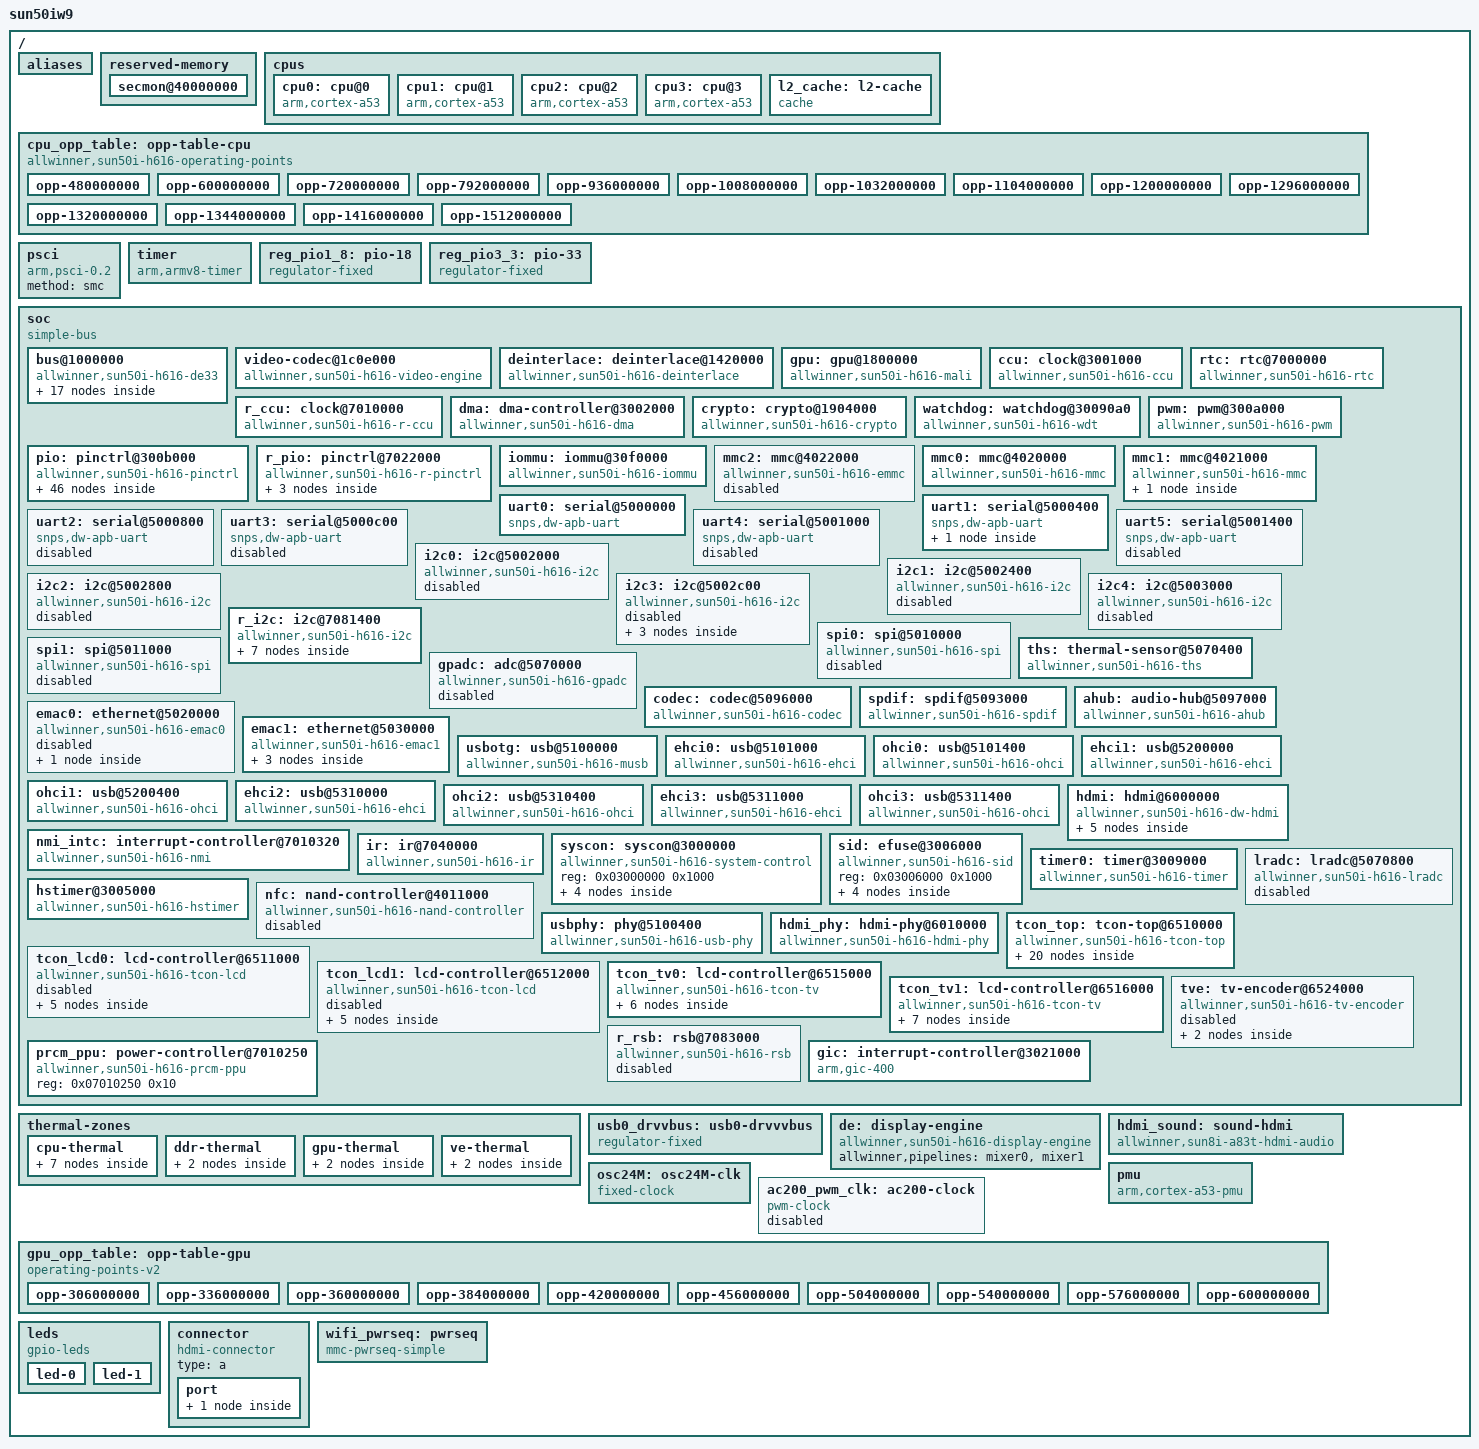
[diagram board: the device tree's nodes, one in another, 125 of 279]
/dts-v1/;

/* dt-bindings from torvalds/linux v6.18 (7d0a66e4bb9081d75c82ec4957c50034cb0ea449), include/ */
#include <dt-bindings/clock/sun50i-h616-ccu.h>
#include <dt-bindings/clock/sun50i-h6-r-ccu.h>
#include <dt-bindings/clock/sun6i-rtc.h>
#include <dt-bindings/clock/sun8i-de2.h>
#include <dt-bindings/clock/sun8i-tcon-top.h>
#include <dt-bindings/reset/sun50i-h616-ccu.h>
#include <dt-bindings/reset/sun50i-h6-r-ccu.h>
#include <dt-bindings/reset/sun8i-de2.h>
#include <dt-bindings/gpio/gpio.h>
#include <dt-bindings/interrupt-controller/arm-gic.h>
#include <dt-bindings/interrupt-controller/irq.h>
#include <dt-bindings/input/linux-event-codes.h>
#include <dt-bindings/leds/common.h>
#include <dt-bindings/thermal/thermal.h>

/ {
	interrupt-parent = <&gic>;
	#address-cells = <2>;
	#size-cells = <2>;
	model = "sun50iw9";

	aliases {
		serial0 = &uart0;
		serial1 = &uart1;
		serial2 = &uart2;
		serial3 = &uart3;
		serial4 = &uart4;
		serial5 = &uart5;
		mmc0 = &mmc0;
		mmc2 = &mmc2;
		spi0 = &spi0;
		spi1 = &spi1;
	};

	reserved-memory {
		#address-cells = <2>;
		#size-cells = <2>;
		ranges;

		/*
		 * 256 KiB reserved for Trusted Firmware-A (BL31).
		 * This is added by BL31 itself, but some bootloaders fail
		 * to propagate this into the DTB handed to kernels.
		 */
		secmon@40000000 {
			reg = <0x0 0x40000000 0x0 0x40000>;
			no-map;
		};
	};

	cpus {
		#address-cells = <1>;
		#size-cells = <0>;

		cpu0: cpu@0 {
			compatible = "arm,cortex-a53";
			device_type = "cpu";
			reg = <0>;
			enable-method = "psci";
			clocks = <&ccu CLK_CPUX>;
			#cooling-cells = <2>;
			i-cache-size = <0x8000>;
			i-cache-line-size = <64>;
			i-cache-sets = <256>;
			d-cache-size = <0x8000>;
			d-cache-line-size = <64>;
			d-cache-sets = <128>;
			next-level-cache = <&l2_cache>;
			operating-points-v2 = <&cpu_opp_table>;
			dynamic-power-coefficient = <202>;
			cpu-supply = <&reg_dcdc2>;
		};

		cpu1: cpu@1 {
			compatible = "arm,cortex-a53";
			device_type = "cpu";
			reg = <1>;
			enable-method = "psci";
			clocks = <&ccu CLK_CPUX>;
			#cooling-cells = <2>;
			i-cache-size = <0x8000>;
			i-cache-line-size = <64>;
			i-cache-sets = <256>;
			d-cache-size = <0x8000>;
			d-cache-line-size = <64>;
			d-cache-sets = <128>;
			next-level-cache = <&l2_cache>;
			operating-points-v2 = <&cpu_opp_table>;
			dynamic-power-coefficient = <202>;
		};

		cpu2: cpu@2 {
			compatible = "arm,cortex-a53";
			device_type = "cpu";
			reg = <2>;
			enable-method = "psci";
			clocks = <&ccu CLK_CPUX>;
			#cooling-cells = <2>;
			i-cache-size = <0x8000>;
			i-cache-line-size = <64>;
			i-cache-sets = <256>;
			d-cache-size = <0x8000>;
			d-cache-line-size = <64>;
			d-cache-sets = <128>;
			next-level-cache = <&l2_cache>;
			operating-points-v2 = <&cpu_opp_table>;
			dynamic-power-coefficient = <202>;
		};

		cpu3: cpu@3 {
			compatible = "arm,cortex-a53";
			device_type = "cpu";
			reg = <3>;
			enable-method = "psci";
			clocks = <&ccu CLK_CPUX>;
			#cooling-cells = <2>;
			i-cache-size = <0x8000>;
			i-cache-line-size = <64>;
			i-cache-sets = <256>;
			d-cache-size = <0x8000>;
			d-cache-line-size = <64>;
			d-cache-sets = <128>;
			next-level-cache = <&l2_cache>;
			operating-points-v2 = <&cpu_opp_table>;
			dynamic-power-coefficient = <202>;
		};

		l2_cache: l2-cache {
			compatible = "cache";
			cache-level = <2>;
			cache-unified;
			cache-size = <0x40000>;
			cache-line-size = <64>;
			cache-sets = <256>;
		};
	};

	cpu_opp_table: opp-table-cpu {
		compatible = "allwinner,sun50i-h616-operating-points";
		nvmem-cells = <&cpu_speed_grade>;
		opp-shared;

		opp-480000000 {
			opp-hz = /bits/ 64 <480000000>;
			opp-microvolt-speed0 = <900000>;
			opp-microvolt-speed1 = <900000>;
			opp-microvolt-speed2 = <900000>;
			opp-microvolt-speed3 = <900000>;
			opp-microvolt-speed4 = <900000>;
			clock-latency-ns = <244144>;
			opp-supported-hw = <0x1f>;
		};

		opp-600000000 {
			opp-hz = /bits/ 64 <600000000>;
			opp-microvolt-speed1 = <900000>;
			opp-microvolt-speed4 = <900000>;
			clock-latency-ns = <244144>;
			opp-supported-hw = <0x12>;
		};

		opp-720000000 {
			opp-hz = /bits/ 64 <720000000>;
			opp-microvolt-speed0 = <900000>;
			opp-microvolt-speed2 = <900000>;
			opp-microvolt-speed3 = <900000>;
			clock-latency-ns = <244144>;
			opp-supported-hw = <0x0d>;
		};

		opp-792000000 {
			opp-hz = /bits/ 64 <792000000>;
			opp-microvolt-speed1 = <900000>;
			opp-microvolt-speed4 = <940000>;
			clock-latency-ns = <244144>;
			opp-supported-hw = <0x12>;
		};

		opp-936000000 {
			opp-hz = /bits/ 64 <936000000>;
			opp-microvolt-speed2 = <900000>;
			opp-microvolt-speed3 = <900000>;
			clock-latency-ns = <244144>;
			opp-supported-hw = <0x0c>;
		};

		opp-1008000000 {
			opp-hz = /bits/ 64 <1008000000>;
			opp-microvolt-speed1 = <940000>;
			opp-microvolt-speed2 = <950000>;
			opp-microvolt-speed3 = <950000>;
			opp-microvolt-speed4 = <1020000>;
			clock-latency-ns = <244144>;
			opp-supported-hw = <0x1e>;
		};

		opp-1032000000 {
			opp-hz = /bits/ 64 <1032000000>;
			opp-microvolt-speed0 = <900000>;
			clock-latency-ns = <244144>;
			opp-supported-hw = <0x01>;
		};

		opp-1104000000 {
			opp-hz = /bits/ 64 <1104000000>;
			opp-microvolt-speed0 = <950000>;
			opp-microvolt-speed2 = <1000000>;
			opp-microvolt-speed3 = <1000000>;
			clock-latency-ns = <244144>;
			opp-supported-hw = <0x0d>;
		};

		opp-1200000000 {
			opp-hz = /bits/ 64 <1200000000>;
			opp-microvolt-speed0 = <1000000>;
			opp-microvolt-speed1 = <1020000>;
			opp-microvolt-speed2 = <1050000>;
			opp-microvolt-speed3 = <1050000>;
			opp-microvolt-speed4 = <1100000>;
			clock-latency-ns = <244144>;
			opp-supported-hw = <0x1f>;
		};

		opp-1296000000 {
			opp-hz = /bits/ 64 <1296000000>;
			opp-microvolt-speed0 = <1050000>;
			clock-latency-ns = <244144>;
			opp-supported-hw = <0x01>;
		};

		opp-1320000000 {
			opp-hz = /bits/ 64 <1320000000>;
			opp-microvolt-speed2 = <1100000>;
			opp-microvolt-speed3 = <1100000>;
			clock-latency-ns = <244144>;
			opp-supported-hw = <0x0c>;
		};

		opp-1344000000 {
			opp-hz = /bits/ 64 <1344000000>;
			opp-microvolt-speed4 = <1120000>;
			clock-latency-ns = <244144>;
			opp-supported-hw = <0x10>;
		};

		opp-1416000000 {
			opp-hz = /bits/ 64 <1416000000>;
			opp-microvolt-speed0 = <1100000>;
			opp-microvolt-speed2 = <1150000>;
			opp-microvolt-speed3 = <1160000>;
			clock-latency-ns = <244144>;
			opp-supported-hw = <0x0d>;
		};

		opp-1512000000 {
			opp-hz = /bits/ 64 <1512000000>;
			opp-microvolt-speed0 = <1150000>;
			opp-microvolt-speed1 = <1100000>;
			opp-microvolt-speed3 = <1100000>;
			clock-latency-ns = <244144>;
			opp-supported-hw = <0x0b>;
		};
	};

	psci {
		compatible = "arm,psci-0.2";
		method = "smc";
	};

	timer {
		compatible = "arm,armv8-timer";
		arm,no-tick-in-suspend;
		interrupts = <GIC_PPI 13
			(GIC_CPU_MASK_SIMPLE(4) | IRQ_TYPE_LEVEL_HIGH)>,
			     <GIC_PPI 14
			(GIC_CPU_MASK_SIMPLE(4) | IRQ_TYPE_LEVEL_HIGH)>,
			     <GIC_PPI 11
			(GIC_CPU_MASK_SIMPLE(4) | IRQ_TYPE_LEVEL_HIGH)>,
			     <GIC_PPI 10
			(GIC_CPU_MASK_SIMPLE(4) | IRQ_TYPE_LEVEL_HIGH)>;
	};

	reg_pio1_8: pio-18 {
		compatible = "regulator-fixed";
		regulator-name = "pio-18";
		regulator-min-microvolt = <1800000>;
		regulator-max-microvolt = <1800000>;
	};

	reg_pio3_3: pio-33 {
		compatible = "regulator-fixed";
		regulator-name = "pio-33";
		regulator-min-microvolt = <3300000>;
		regulator-max-microvolt = <3300000>;
	};

	soc {
		compatible = "simple-bus";
		#address-cells = <1>;
		#size-cells = <1>;
		ranges = <0x0 0x0 0x0 0x40000000>;

		bus@1000000 {
			compatible = "allwinner,sun50i-h616-de33",
				     "allwinner,sun50i-a64-de2";
			reg = <0x1000000 0x400000>;
			allwinner,sram = <&sram_c 1>;
			#address-cells = <1>;
			#size-cells = <1>;
			ranges = <0 0x1000000 0x400000>;

			display_clocks: clock@8000 {
				compatible = "allwinner,sun50i-h616-de33-clk";
				reg = <0x8000 0x100>;
				clocks = <&ccu CLK_BUS_DE>, <&ccu CLK_DE>;
				clock-names = "bus", "mod";
				resets = <&ccu RST_BUS_DE>;
				#clock-cells = <1>;
				#reset-cells = <1>;
			};

			writeback: writeback@11000 {
				compatible = "allwinner,sun50i-h616-de33-wb";
				reg = <0x11000 0x1000>, <0x8200 0x20>;
				reg-names = "writeback", "rcq";
				clocks = <&display_clocks CLK_BUS_MIXER0>,
					 <&display_clocks CLK_WB>;
				clock-names = "bus", "mod";
				resets = <&display_clocks RST_WB>;
				interrupts = <GIC_SPI 88 IRQ_TYPE_LEVEL_HIGH>;
				allwinner,top = <&display_clocks>;

				ports {
					#address-cells = <1>;
					#size-cells = <0>;

					writeback_in: port@0 {
						#address-cells = <1>;
						#size-cells = <0>;
						reg = <0>;

						writeback_in_mixer0: endpoint@0 {
							reg = <0>;
							remote-endpoint = <&mixer0_out_writeback>;
						};

						writeback_in_mixer1: endpoint@1 {
							reg = <1>;
							remote-endpoint = <&mixer1_out_writeback>;
						};
					};
				};
			};

			planes: planes@100000 {
				compatible = "allwinner,sun50i-h616-de33-planes";
				reg = <0x100000 0x180000>;
				iommus = <&iommu 0>;
				allwinner,plane-mapping = <&display_clocks>;
			};

			mixer0: mixer@280000 {
				compatible = "allwinner,sun50i-h616-de33-mixer-0";
				reg = <0x280000 0x20000>,
				      <0x8100 0x40>;
				reg-names = "display", "top";
				clocks = <&display_clocks CLK_BUS_MIXER0>,
					 <&display_clocks CLK_MIXER0>;
				clock-names = "bus", "mod";
				resets = <&display_clocks RST_MIXER0>;
				iommus = <&iommu 0>;
				allwinner,planes = <&planes>;

				ports {
					#address-cells = <1>;
					#size-cells = <0>;

					mixer0_out: port@1 {
						#address-cells = <1>;
						#size-cells = <0>;
						reg = <1>;

						mixer0_out_tcon_top_mixer0: endpoint@0 {
							reg = <0>;
							remote-endpoint =
								<&tcon_top_mixer0_in_mixer0>;
						};

						mixer0_out_writeback: endpoint@1 {
							reg = <1>;
							remote-endpoint = <&writeback_in_mixer0>;
						};
					};
				};
			};

			mixer1: mixer@2a0000 {
				compatible = "allwinner,sun50i-h616-de33-mixer-0";
				reg = <0x2a0000 0x20000>,
				      <0x8140 0x40>;
				reg-names = "display", "top";
				clocks = <&display_clocks CLK_BUS_MIXER0>,
					 <&display_clocks CLK_MIXER1>;
				clock-names = "bus", "mod";
				resets = <&display_clocks RST_MIXER1>;
				allwinner,planes = <&planes>;

				ports {
					#address-cells = <1>;
					#size-cells = <0>;

					mixer1_out: port@1 {
						#address-cells = <1>;
						#size-cells = <0>;
						reg = <1>;

						mixer1_out_tcon_top_mixer1: endpoint@0 {
							reg = <0>;
							remote-endpoint =
								<&tcon_top_mixer1_in_mixer1>;
						};

						mixer1_out_writeback: endpoint@1 {
							reg = <1>;
							remote-endpoint = <&writeback_in_mixer1>;
						};
					};
				};
			};
		};

		video-codec@1c0e000 {
			compatible = "allwinner,sun50i-h616-video-engine";
			reg = <0x01c0e000 0x2000>;
			clocks = <&ccu CLK_BUS_VE>, <&ccu CLK_VE>,
				 <&ccu CLK_MBUS_VE>;
			clock-names = "ahb", "mod", "ram";
			resets = <&ccu RST_BUS_VE>;
			interrupts = <GIC_SPI 93 IRQ_TYPE_LEVEL_HIGH>;
			iommus = <&iommu 3>, <&iommu 2>;
			allwinner,sram = <&ve_sram 1>, <&sram_c 1>;
		};

		deinterlace: deinterlace@1420000 {
			compatible = "allwinner,sun50i-h616-deinterlace";
			reg = <0x01420000 0x40000>;
			clocks = <&ccu CLK_BUS_DEINTERLACE>,
				 <&ccu CLK_DEINTERLACE>;
			clock-names = "bus", "mod";
			resets = <&ccu RST_BUS_DEINTERLACE>;
			interrupts = <GIC_SPI 89 IRQ_TYPE_LEVEL_HIGH>;
			iommus = <&iommu 1>;
		};

		gpu: gpu@1800000 {
			compatible = "allwinner,sun50i-h616-mali",
				     "arm,mali-bifrost";
			reg = <0x1800000 0x40000>;
			interrupts = <GIC_SPI 95 IRQ_TYPE_LEVEL_HIGH>,
				     <GIC_SPI 96 IRQ_TYPE_LEVEL_HIGH>,
				     <GIC_SPI 97 IRQ_TYPE_LEVEL_HIGH>;
			interrupt-names = "job", "mmu", "gpu";
			clocks = <&ccu CLK_GPU0>, <&ccu CLK_BUS_GPU>;
			clock-names = "core", "bus";
			power-domains = <&prcm_ppu 2>;
			resets = <&ccu RST_BUS_GPU>;
			#cooling-cells = <2>;
			operating-points-v2 = <&gpu_opp_table>;
			status = "okay";
			mali-supply = <&reg_dcdc1>;
		};

		ccu: clock@3001000 {
			compatible = "allwinner,sun50i-h616-ccu";
			reg = <0x03001000 0x1000>;
			clocks = <&osc24M>, <&rtc CLK_OSC32K>, <&rtc CLK_IOSC>;
			clock-names = "hosc", "losc", "iosc";
			#clock-cells = <1>;
			#reset-cells = <1>;
		};

		rtc: rtc@7000000 {
			compatible = "allwinner,sun50i-h616-rtc";
			reg = <0x07000000 0x400>;
			interrupts = <GIC_SPI 104 IRQ_TYPE_LEVEL_HIGH>;
			clocks = <&r_ccu CLK_R_APB1_RTC>, <&osc24M>,
				 <&ccu CLK_PLL_SYSTEM_32K>;
			clock-names = "bus", "hosc",
				      "pll-32k";
			#clock-cells = <1>;
		};

		r_ccu: clock@7010000 {
			compatible = "allwinner,sun50i-h616-r-ccu";
			reg = <0x07010000 0x210>;
			clocks = <&osc24M>, <&rtc CLK_OSC32K>, <&rtc CLK_IOSC>,
				 <&ccu CLK_PLL_PERIPH0>;
			clock-names = "hosc", "losc", "iosc", "pll-periph";
			#clock-cells = <1>;
			#reset-cells = <1>;
		};

		dma: dma-controller@3002000 {
			compatible = "allwinner,sun50i-h616-dma",
				     "allwinner,sun50i-a100-dma";
			reg = <0x03002000 0x1000>;
			interrupts = <GIC_SPI 42 IRQ_TYPE_LEVEL_HIGH>;
			clocks = <&ccu CLK_BUS_DMA>, <&ccu CLK_MBUS_DMA>;
			clock-names = "bus", "mbus";
			dma-channels = <16>;
			dma-requests = <49>;
			resets = <&ccu RST_BUS_DMA>;
			#dma-cells = <1>;
		};

		crypto: crypto@1904000 {
			compatible = "allwinner,sun50i-h616-crypto";
			reg = <0x01904000 0x800>;
			interrupts = <GIC_SPI 91 IRQ_TYPE_LEVEL_HIGH>;
			clocks = <&ccu CLK_BUS_CE>, <&ccu CLK_CE>,
				 <&ccu CLK_MBUS_CE>, <&rtc CLK_IOSC>;
			clock-names = "bus", "mod", "ram", "trng";
			resets = <&ccu RST_BUS_CE>;
		};

		watchdog: watchdog@30090a0 {
			compatible = "allwinner,sun50i-h616-wdt",
				     "allwinner,sun6i-a31-wdt";
			reg = <0x030090a0 0x20>;
			interrupts = <GIC_SPI 50 IRQ_TYPE_LEVEL_HIGH>;
			clocks = <&osc24M>;
		};

		pwm: pwm@300a000 {
			compatible = "allwinner,sun50i-h616-pwm";
			reg = <0x0300a000 0x400>;
			clocks = <&ccu CLK_BUS_PWM>,
				 <&osc24M>,
				 <&ccu CLK_APB1>;
			clock-names = "bus", "hosc", "apb0";
			resets = <&ccu RST_BUS_PWM>;
			#pwm-cells = <0x3>;
			status = "okay";
		};

		pio: pinctrl@300b000 {
			compatible = "allwinner,sun50i-h616-pinctrl";
			reg = <0x0300b000 0x400>;
			interrupts = <GIC_SPI 51 IRQ_TYPE_LEVEL_HIGH>,
				     <GIC_SPI 52 IRQ_TYPE_LEVEL_HIGH>,
				     <GIC_SPI 53 IRQ_TYPE_LEVEL_HIGH>,
				     <GIC_SPI 43 IRQ_TYPE_LEVEL_HIGH>,
				     <GIC_SPI 54 IRQ_TYPE_LEVEL_HIGH>,
				     <GIC_SPI 55 IRQ_TYPE_LEVEL_HIGH>,
				     <GIC_SPI 56 IRQ_TYPE_LEVEL_HIGH>,
				     <GIC_SPI 57 IRQ_TYPE_LEVEL_HIGH>;
			clocks = <&ccu CLK_APB1>, <&osc24M>, <&rtc CLK_OSC32K>;
			clock-names = "apb", "hosc", "losc";
			gpio-controller;
			#gpio-cells = <3>;
			interrupt-controller;
			#interrupt-cells = <3>;
			vcc-pg-supply = <&reg_pio1_8>;

			uart0_ph_pins: uart0-ph-pins {
				pins = "PH0", "PH1";
				function = "uart0";
				bias-pull-up;
			};

			sdc0_pins_a: sdc0-a-pins {
				pins = "PF0", "PF1", "PF2", "PF3", "PF4", "PF5";
				function = "mmc0";
				drive-strength = <30>;
				bias-pull-up;
			};

			sdc1_pins_a: sdc1-a-pins {
				pins = "PG0", "PG1", "PG2", "PG3", "PG4", "PG5";
				function = "mmc1";
				drive-strength = <30>;
				bias-pull-up;
			};

			sdc2_pins_a: sdc2-a-pins {
				pins = "PC1", "PC5", "PC6", "PC8", "PC9", "PC10", "PC11", "PC13", "PC14", "PC15", "PC16";
				function = "mmc2";
				drive-strength = <30>;
				bias-pull-up;
			};

			sdc2_pins_c: sdc2-c-pins {
				pins = "PC0";
				function = "mmc2";
				drive-strength = <30>;
				bias-pull-down;
			};

			uart1_ph_pins: uart1-ph-pins {
				pins = "PG6", "PG7", "PG8", "PG9";
				function = "uart1";
			};

			uart2_ph_pins: uart2-ph-pins {
				pins = "PG15", "PG16";
				function = "uart2";
			};

			uart3_ph_pins: uart3-ph-pins {
				pins = "PI9", "PI10";
				function = "uart3";
			};

			uart4_ph_pins: uart4-ph-pins {
				pins = "PI13", "PI14";
				function = "uart4";
			};

			uart5_ph_pins: uart5-ph-pins {
				pins = "PH2", "PH3";
				function = "uart5";
			};

			s_cir0_pins_a: s-cir0-a-pins {
				pins = "PH10";
				function = "ir_rx";
				drive-strength = <10>;
				bias-pull-up;
			};

			twi0_pins_a: twi0-a-pins {
				pins = "PI5", "PI6";
				function = "i2c0";
				drive-strength = <10>;
				bias-pull-up;
			};

			twi1_pins_a: twi1-a-pins {
				pins = "PH0", "PH1";
				function = "i2c1";
				drive-strength = <10>;
				bias-pull-up;
			};

			twi2_pins_a: twi2-a-pins {
				pins = "PH2", "PH3";
				function = "i2c2";
				drive-strength = <10>;
				bias-pull-up;
			};

			twi3_pins_a: twi3-a-pins {
				pins = "PG17", "PG18";
				function = "i2c3";
				drive-strength = <10>;
				bias-pull-up;
			};

			twi4_pins_a: twi4-a-pins {
				pins = "PG15", "PG16";
				function = "i2c4";
				drive-strength = <10>;
				bias-pull-up;
			};

			spi1_pins_a: spi1-a-pins {
				pins = "PH6", "PH7", "PH8";
				function = "spi1";
				drive-strength = <30>;
				bias-disable;
			};

			spi1_pins_b: spi1-b-pins {
				pins = "PH5", "PH9";
				function = "spi1";
				drive-strength = <30>;
				bias-pull-up;
			};

			gmac0_pins_a: gmac0-a-pins {
				pins = "PI0", "PI1", "PI2", "PI3", "PI4", "PI5", "PI6", "PI7", "PI8", "PI9", "PI10", "PI11", "PI12", "PI13", "PI14", "PI15", "PI16";
				function = "emac0";
				drive-strength = <10>;
				bias-pull-up;
			};

			gmac1_pins_a: gmac1-a-pins {
				pins = "PA0", "PA1", "PA2", "PA3", "PA4", "PA5", "PA6", "PA7", "PA8", "PA9";
				function = "emac1";
				drive-strength = <10>;
				bias-pull-up;
			};

			spdif_pins_a: spdif-a-pins {
				pins = "PH4";
				function = "spdif";
				drive-strength = <20>;
				bias-disable;
			};

			clk_losc_pins_a: losc-out-a-pins {
				pins = "PG10";
				function = "clock";
				drive-strength = <30>;
				bias-pull-up;
			};

			ext_rgmii_pins: rgmii-pins {
				pins = "PI0", "PI1", "PI2", "PI3", "PI4",
				       "PI5", "PI7", "PI8", "PI9", "PI10",
				       "PI11", "PI12", "PI13", "PI14", "PI15",
				       "PI16";
				function = "emac0";
				drive-strength = <40>;
			};

			i2c0_pins: i2c0-pins {
				pins = "PI5", "PI6";
				function = "i2c0";
			};

			/omit-if-no-ref/
			i2c3_pa_pins: i2c3-pa-pins {
				pins = "PA10", "PA11";
				function = "i2c3";
				bias-pull-up;
			};

			i2c3_ph_pins: i2c3-ph-pins {
				pins = "PH4", "PH5";
				function = "i2c3";
			};

			ir_rx_pin: ir-rx-pin {
				pins = "PH10";
				function = "ir_rx";
			};

			mmc0_pins: mmc0-pins {
				pins = "PF0", "PF1", "PF2", "PF3",
				       "PF4", "PF5";
				function = "mmc0";
				drive-strength = <30>;
				bias-pull-up;
			};

			/omit-if-no-ref/
			mmc1_pins: mmc1-pins {
				pins = "PG0", "PG1", "PG2", "PG3",
				       "PG4", "PG5";
				function = "mmc1";
				drive-strength = <30>;
				bias-pull-up;
			};

			mmc2_pins: mmc2-pins {
				pins = "PC0", "PC1", "PC5", "PC6",
				       "PC8", "PC9", "PC10", "PC11",
				       "PC13", "PC14", "PC15", "PC16";
				function = "mmc2";
				drive-strength = <30>;
				bias-pull-up;
			};

			/omit-if-no-ref/
			nand_pins: nand-pins {
				pins = "PC0", "PC1", "PC2", "PC5", "PC8", "PC9",
				       "PC10", "PC11", "PC12", "PC13", "PC14",
				       "PC15", "PC16";
				function = "nand0";
			};

			/omit-if-no-ref/
			nand_cs0_pin: nand-cs0-pin {
				pins = "PC4";
				function = "nand0";
				bias-pull-up;
			};

			/omit-if-no-ref/
			nand_cs1_pin: nand-cs1-pin {
				pins = "PC3";
				function = "nand0";
				bias-pull-up;
			};

			/omit-if-no-ref/
			nand_rb0_pin: nand-rb0-pin {
				pins = "PC6";
				function = "nand0";
				bias-pull-up;
			};

			/omit-if-no-ref/
			nand_rb1_pin: nand-rb1-pin {
				pins = "PC7";
				function = "nand0";
				bias-pull-up;
			};

			/omit-if-no-ref/
			rmii_pins: rmii-pins {
				pins = "PA0", "PA1", "PA2", "PA3", "PA4",
				       "PA5", "PA6", "PA7", "PA8", "PA9";
				function = "emac1";
				drive-strength = <40>;
			};

			/omit-if-no-ref/
			pwm0_pin: pwm0-pin {
				pins = "PD28";
				function = "pwm0";
			};

			/omit-if-no-ref/
			pwm5_pin: pwm5-pin {
				pins = "PA12";
				function = "pwm5";
			};

			/omit-if-no-ref/
			spi0_pins: spi0-pins {
				pins = "PC0", "PC2", "PC4";
				function = "spi0";
			};

			/omit-if-no-ref/
			spi0_cs0_pin: spi0-cs0-pin {
				pins = "PC3";
				function = "spi0";
			};

			/omit-if-no-ref/
			spi1_pins: spi1-pins {
				pins = "PH6", "PH7", "PH8";
				function = "spi1";
			};

			/omit-if-no-ref/
			spi1_cs0_pin: spi1-cs0-pin {
				pins = "PH5";
				function = "spi1";
			};

			spdif_tx_pin: spdif-tx-pin {
				pins = "PH4";
				function = "spdif";
			};

			/omit-if-no-ref/
			uart1_pins: uart1-pins {
				pins = "PG6", "PG7";
				function = "uart1";
			};

			/omit-if-no-ref/
			uart1_rts_cts_pins: uart1-rts-cts-pins {
				pins = "PG8", "PG9";
				function = "uart1";
			};

			/omit-if-no-ref/
			x32clk_fanout_pin: x32clk-fanout-pin {
				pins = "PG10";
				function = "clock";
			};
		};

		r_pio: pinctrl@7022000 {
			compatible = "allwinner,sun50i-h616-r-pinctrl";
			reg = <0x07022000 0x400>;
			clocks = <&r_ccu CLK_R_APB1>, <&osc24M>,
				 <&rtc CLK_OSC32K>;
			clock-names = "apb", "hosc", "losc";
			gpio-controller;
			#gpio-cells = <3>;

			s_twi0_pins_a: s-twi0-a-pins {
				pins = "PL0", "PL1";
				function = "s_i2c";
				drive-strength = <20>;
				bias-pull-up;
			};

			/omit-if-no-ref/
			r_i2c_pins: r-i2c-pins {
				pins = "PL0", "PL1";
				function = "s_i2c";
			};

			r_rsb_pins: r-rsb-pins {
				pins = "PL0", "PL1";
				function = "s_rsb";
			};
		};

		iommu: iommu@30f0000 {
			compatible = "allwinner,sun50i-h616-iommu";
			reg = <0x030f0000 0x10000>;
			interrupts = <GIC_SPI 61 IRQ_TYPE_LEVEL_HIGH>;
			clocks = <&ccu CLK_BUS_IOMMU>;
			resets = <&ccu RST_BUS_IOMMU>;
			#iommu-cells = <1>;
		};

		mmc2: mmc@4022000 {
			compatible = "allwinner,sun50i-h616-emmc",
				     "allwinner,sun50i-a100-emmc";
			reg = <0x04022000 0x1000>;
			clocks = <&ccu CLK_BUS_MMC2>, <&ccu CLK_MMC2>;
			clock-names = "ahb", "mmc";
			resets = <&ccu RST_BUS_MMC2>;
			reset-names = "ahb";
			interrupts = <GIC_SPI 37 IRQ_TYPE_LEVEL_HIGH>;
			cap-sd-highspeed;
			cap-mmc-highspeed;
			mmc-ddr-3_3v;
			cap-sdio-irq;
			#address-cells = <1>;
			#size-cells = <0>;
			pinctrl-names = "default";
			pinctrl-0 = <&sdc2_pins_a>, <&sdc2_pins_c>;
			bus-width = <8>;
			non-removable;
			max-frequency = <100000000>;
			no-sdio;
			no-sd;
			status = "disabled";
			mmc-ddr-1_8v;
			mmc-hs200-1_8v;
			vmmc-supply = <&reg_dldo1>;
			vqmmc-supply = <&reg_aldo1>;
		};

		mmc0: mmc@4020000 {
			compatible = "allwinner,sun50i-h616-mmc",
				     "allwinner,sun50i-a100-mmc";
			reg = <0x04020000 0x1000>;
			clocks = <&ccu CLK_BUS_MMC0>, <&ccu CLK_MMC0>;
			clock-names = "ahb", "mmc";
			resets = <&ccu RST_BUS_MMC0>;
			reset-names = "ahb";
			interrupts = <GIC_SPI 35 IRQ_TYPE_LEVEL_HIGH>;
			cap-sd-highspeed;
			cap-mmc-highspeed;
			mmc-ddr-3_3v;
			cap-sdio-irq;
			#address-cells = <1>;
			#size-cells = <0>;
			pinctrl-names = "default";
			pinctrl-0 = <&sdc0_pins_a>;
			max-frequency = <150000000>;
			bus-width = <4>;
			no-sdio;
			no-mmc;
			status = "okay";
			vmmc-supply = <&reg_dldo1>;
			cd-gpios = <&pio 5 6 (GPIO_ACTIVE_LOW | GPIO_PULL_UP)>;
		};

		mmc1: mmc@4021000 {
			compatible = "allwinner,sun50i-h616-mmc",
				     "allwinner,sun50i-a100-mmc";
			reg = <0x04021000 0x1000>;
			clocks = <&ccu CLK_BUS_MMC1>, <&ccu CLK_MMC1>;
			clock-names = "ahb", "mmc";
			resets = <&ccu RST_BUS_MMC1>;
			reset-names = "ahb";
			interrupts = <GIC_SPI 36 IRQ_TYPE_LEVEL_HIGH>;
			cap-sd-highspeed;
			cap-mmc-highspeed;
			mmc-ddr-3_3v;
			cap-sdio-irq;
			#address-cells = <1>;
			#size-cells = <0>;
			pinctrl-names = "default";
			pinctrl-0 = <&sdc1_pins_a>;
			max-frequency = <150000000>;
			bus-width = <4>;
			no-mmc;
			keep-power-in-suspend;
			status = "okay";
			no-sd;
			vmmc-supply = <&reg_dldo1>;
			vqmmc-supply = <&reg_aldo1>;
			mmc-pwrseq = <&wifi_pwrseq>;
			non-removable;

			sdio_wifi: wifi@1 {
				reg = <1>;
			};
		};

		uart0: serial@5000000 {
			compatible = "snps,dw-apb-uart";
			reg = <0x05000000 0x400>;
			interrupts = <GIC_SPI 0 IRQ_TYPE_LEVEL_HIGH>;
			reg-shift = <2>;
			reg-io-width = <4>;
			clocks = <&ccu CLK_BUS_UART0>;
			dmas = <&dma 14>, <&dma 14>;
			dma-names = "tx", "rx";
			resets = <&ccu RST_BUS_UART0>;
			status = "okay";
			pinctrl-names = "default";
			pinctrl-0 = <&uart0_ph_pins>;
		};

		uart1: serial@5000400 {
			compatible = "snps,dw-apb-uart";
			reg = <0x05000400 0x400>;
			interrupts = <GIC_SPI 1 IRQ_TYPE_LEVEL_HIGH>;
			reg-shift = <2>;
			reg-io-width = <4>;
			clocks = <&ccu CLK_BUS_UART1>;
			dmas = <&dma 15>, <&dma 15>;
			dma-names = "tx", "rx";
			resets = <&ccu RST_BUS_UART1>;
			uart-has-rtscts;
			status = "okay";
			pinctrl-names = "default";
			pinctrl-0 = <&uart1_ph_pins>;

			bt: bluetooth {
				reset-gpios = <&pio 6 19 GPIO_ACTIVE_LOW>;
				device-wakeup-gpios = <&pio 6 17 GPIO_ACTIVE_HIGH>;
			};
		};

		uart2: serial@5000800 {
			compatible = "snps,dw-apb-uart";
			reg = <0x05000800 0x400>;
			interrupts = <GIC_SPI 2 IRQ_TYPE_LEVEL_HIGH>;
			reg-shift = <2>;
			reg-io-width = <4>;
			clocks = <&ccu CLK_BUS_UART2>;
			dmas = <&dma 16>, <&dma 16>;
			dma-names = "tx", "rx";
			resets = <&ccu RST_BUS_UART2>;
			uart-has-rtscts;
			status = "disabled";
			pinctrl-names = "default";
			pinctrl-0 = <&uart2_ph_pins>;
		};

		uart3: serial@5000c00 {
			compatible = "snps,dw-apb-uart";
			reg = <0x05000c00 0x400>;
			interrupts = <GIC_SPI 3 IRQ_TYPE_LEVEL_HIGH>;
			reg-shift = <2>;
			reg-io-width = <4>;
			clocks = <&ccu CLK_BUS_UART3>;
			dmas = <&dma 17>, <&dma 17>;
			dma-names = "tx", "rx";
			resets = <&ccu RST_BUS_UART3>;
			uart-has-rtscts;
			status = "disabled";
			pinctrl-names = "default";
			pinctrl-0 = <&uart3_ph_pins>;
		};

		uart4: serial@5001000 {
			compatible = "snps,dw-apb-uart";
			reg = <0x05001000 0x400>;
			interrupts = <GIC_SPI 4 IRQ_TYPE_LEVEL_HIGH>;
			reg-shift = <2>;
			reg-io-width = <4>;
			clocks = <&ccu CLK_BUS_UART4>;
			dmas = <&dma 18>, <&dma 18>;
			dma-names = "tx", "rx";
			resets = <&ccu RST_BUS_UART4>;
			uart-has-rtscts;
			status = "disabled";
			pinctrl-names = "default";
			pinctrl-0 = <&uart4_ph_pins>;
		};

		uart5: serial@5001400 {
			compatible = "snps,dw-apb-uart";
			reg = <0x05001400 0x400>;
			interrupts = <GIC_SPI 5 IRQ_TYPE_LEVEL_HIGH>;
			reg-shift = <2>;
			reg-io-width = <4>;
			clocks = <&ccu CLK_BUS_UART5>;
			dmas = <&dma 19>, <&dma 19>;
			dma-names = "tx", "rx";
			resets = <&ccu RST_BUS_UART5>;
			status = "disabled";
			pinctrl-names = "default";
			pinctrl-0 = <&uart5_ph_pins>;
		};

		i2c0: i2c@5002000 {
			compatible = "allwinner,sun50i-h616-i2c",
				     "allwinner,sun8i-v536-i2c",
				     "allwinner,sun6i-a31-i2c";
			reg = <0x05002000 0x400>;
			interrupts = <GIC_SPI 6 IRQ_TYPE_LEVEL_HIGH>;
			clocks = <&ccu CLK_BUS_I2C0>;
			dmas = <&dma 43>, <&dma 43>;
			dma-names = "rx", "tx";
			resets = <&ccu RST_BUS_I2C0>;
			#address-cells = <1>;
			#size-cells = <0>;
			status = "disabled";
			clock-frequency = <400000>;
			pinctrl-names = "default";
			pinctrl-0 = <&twi0_pins_a>;
		};

		i2c1: i2c@5002400 {
			compatible = "allwinner,sun50i-h616-i2c",
				     "allwinner,sun8i-v536-i2c",
				     "allwinner,sun6i-a31-i2c";
			reg = <0x05002400 0x400>;
			interrupts = <GIC_SPI 7 IRQ_TYPE_LEVEL_HIGH>;
			clocks = <&ccu CLK_BUS_I2C1>;
			dmas = <&dma 44>, <&dma 44>;
			dma-names = "rx", "tx";
			resets = <&ccu RST_BUS_I2C1>;
			#address-cells = <1>;
			#size-cells = <0>;
			status = "disabled";
			clock-frequency = <400000>;
			pinctrl-names = "default";
			pinctrl-0 = <&twi1_pins_a>;
		};

		i2c2: i2c@5002800 {
			compatible = "allwinner,sun50i-h616-i2c",
				     "allwinner,sun8i-v536-i2c",
				     "allwinner,sun6i-a31-i2c";
			reg = <0x05002800 0x400>;
			interrupts = <GIC_SPI 8 IRQ_TYPE_LEVEL_HIGH>;
			clocks = <&ccu CLK_BUS_I2C2>;
			dmas = <&dma 45>, <&dma 45>;
			dma-names = "rx", "tx";
			resets = <&ccu RST_BUS_I2C2>;
			#address-cells = <1>;
			#size-cells = <0>;
			status = "disabled";
			clock-frequency = <100000>;
			pinctrl-names = "default";
			pinctrl-0 = <&twi2_pins_a>;
		};

		i2c3: i2c@5002c00 {
			compatible = "allwinner,sun50i-h616-i2c",
				     "allwinner,sun8i-v536-i2c",
				     "allwinner,sun6i-a31-i2c";
			reg = <0x05002c00 0x400>;
			interrupts = <GIC_SPI 9 IRQ_TYPE_LEVEL_HIGH>;
			clocks = <&ccu CLK_BUS_I2C3>;
			dmas = <&dma 46>, <&dma 46>;
			dma-names = "rx", "tx";
			resets = <&ccu RST_BUS_I2C3>;
			#address-cells = <1>;
			#size-cells = <0>;
			status = "disabled";
			clock-frequency = <400000>;
			pinctrl-names = "default";
			pinctrl-0 = <&twi3_pins_a>;

			ac200: mfd@10 {
				compatible = "x-powers,ac200";
				reg = <0x10>;
				clocks = <&ac200_pwm_clk>;
				status = "disabled";

				ac200_ephy_ctl: ethernet-phy-control {
					compatible = "x-powers,ac200-ephy-ctl";
					#clock-cells = <0>;
					#reset-cells = <0>;
					status = "disabled";
				};

				ac200_codec: codec {
					#sound-dai-cells = <0>;
					compatible = "x-powers,ac200-codec";
					status = "disabled";
				};
			};
		};

		i2c4: i2c@5003000 {
			compatible = "allwinner,sun50i-h616-i2c",
				     "allwinner,sun8i-v536-i2c",
				     "allwinner,sun6i-a31-i2c";
			reg = <0x05003000 0x400>;
			interrupts = <GIC_SPI 10 IRQ_TYPE_LEVEL_HIGH>;
			clocks = <&ccu CLK_BUS_I2C4>;
			dmas = <&dma 47>, <&dma 47>;
			dma-names = "rx", "tx";
			resets = <&ccu RST_BUS_I2C4>;
			#address-cells = <1>;
			#size-cells = <0>;
			status = "disabled";
			clock-frequency = <400000>;
			pinctrl-names = "default";
			pinctrl-0 = <&twi4_pins_a>;
		};

		r_i2c: i2c@7081400 {
			compatible = "allwinner,sun50i-h616-i2c",
				     "allwinner,sun8i-v536-i2c",
				     "allwinner,sun6i-a31-i2c";
			reg = <0x07081400 0x400>;
			interrupts = <GIC_SPI 105 IRQ_TYPE_LEVEL_HIGH>;
			clocks = <&r_ccu CLK_R_APB2_I2C>;
			dmas = <&dma 48>, <&dma 48>;
			dma-names = "rx", "tx";
			resets = <&r_ccu RST_R_APB2_I2C>;
			#address-cells = <1>;
			#size-cells = <0>;
			status = "okay";
			clock-frequency = <400000>;
			pinctrl-names = "default";
			pinctrl-0 = <&s_twi0_pins_a>;

			pmu0: pmic@36 {
				compatible = "x-powers,axp313a";
				reg = <0x36>;

				regulators {
					reg_dcdc1: dcdc1 {
						regulator-name = "axp1530-dcdc1";
						regulator-always-on;
						regulator-min-microvolt = <950000>;
						regulator-max-microvolt = <950000>;
					};

					reg_dcdc2: dcdc2 {
						regulator-name = "axp1530-dcdc2";
						regulator-ramp-delay = <200>;
						regulator-always-on;
						regulator-min-microvolt = <900000>;
						regulator-max-microvolt = <1160000>;
					};

					reg_dcdc3: dcdc3 {
						regulator-name = "axp1530-dcdc3";
						regulator-min-microvolt = <500000>;
						regulator-max-microvolt = <1840000>;
						regulator-always-on;
					};

					reg_aldo1: aldo1 {
						regulator-name = "axp1530-aldo1";
						regulator-min-microvolt = <500000>;
						regulator-max-microvolt = <3500000>;
						regulator-always-on;
					};

					reg_dldo1: dldo1 {
						regulator-name = "axp1530-dldo1";
						regulator-min-microvolt = <500000>;
						regulator-max-microvolt = <3500000>;
						regulator-always-on;
					};
				};
			};
		};

		spi0: spi@5010000 {
			compatible = "allwinner,sun50i-h616-spi",
				     "allwinner,sun8i-h3-spi";
			reg = <0x05010000 0x1000>;
			interrupts = <GIC_SPI 12 IRQ_TYPE_LEVEL_HIGH>;
			clocks = <&ccu CLK_BUS_SPI0>, <&ccu CLK_SPI0>;
			clock-names = "ahb", "mod";
			dmas = <&dma 22>, <&dma 22>;
			dma-names = "rx", "tx";
			resets = <&ccu RST_BUS_SPI0>;
			#address-cells = <1>;
			#size-cells = <0>;
			clock-frequency = <100000000>;
			status = "disabled";
		};

		spi1: spi@5011000 {
			compatible = "allwinner,sun50i-h616-spi",
				     "allwinner,sun8i-h3-spi";
			reg = <0x05011000 0x1000>;
			interrupts = <GIC_SPI 13 IRQ_TYPE_LEVEL_HIGH>;
			clocks = <&ccu CLK_BUS_SPI1>, <&ccu CLK_SPI1>;
			clock-names = "ahb", "mod";
			dmas = <&dma 23>, <&dma 23>;
			dma-names = "rx", "tx";
			resets = <&ccu RST_BUS_SPI1>;
			#address-cells = <1>;
			#size-cells = <0>;
			clock-frequency = <100000000>;
			status = "disabled";
			pinctrl-names = "default";
			pinctrl-0 = <&spi1_pins_a>, <&spi1_pins_b>;
		};

		ths: thermal-sensor@5070400 {
			compatible = "allwinner,sun50i-h616-ths";
			reg = <0x05070400 0x400>;
			interrupts = <GIC_SPI 19 IRQ_TYPE_LEVEL_HIGH>;
			clocks = <&ccu CLK_BUS_THS>;
			clock-names = "bus";
			resets = <&ccu RST_BUS_THS>;
			nvmem-cell-names = "calibration";
			allwinner,sram = <&syscon>;
			#thermal-sensor-cells = <1>;
			nvmem-cells = <&ths_calibration>;
		};

		gpadc: adc@5070000 {
			compatible = "allwinner,sun50i-h616-gpadc",
				     "allwinner,sun20i-d1-gpadc";
			reg = <0x05070000 0x400>;
			clocks = <&ccu CLK_BUS_GPADC>;
			resets = <&ccu RST_BUS_GPADC>;
			interrupts = <GIC_SPI 18 IRQ_TYPE_LEVEL_HIGH>;
			status = "disabled";
			#io-channel-cells = <1>;
		};

		codec: codec@5096000 {
			#sound-dai-cells = <0>;
			compatible = "allwinner,sun50i-h616-codec";
			reg = <0x05096000 0x31c>;
			interrupts = <GIC_SPI 58 IRQ_TYPE_LEVEL_HIGH>;
			clocks = <&ccu CLK_BUS_AUDIO_CODEC>,
				 <&ccu CLK_AUDIO_CODEC_1X>;
			clock-names = "apb", "codec";
			resets = <&ccu RST_BUS_AUDIO_CODEC>;
			dmas = <&dma 6>;
			dma-names = "tx";
			status = "okay";
			allwinner,audio-routing = "Line Out", "LINEOUT";
		};

		spdif: spdif@5093000 {
			compatible = "allwinner,sun50i-h616-spdif";
			reg = <0x05093000 0x400>;
			interrupts = <GIC_SPI 21 IRQ_TYPE_LEVEL_HIGH>;
			clocks = <&ccu CLK_BUS_SPDIF>, <&ccu CLK_SPDIF>;
			clock-names = "apb", "spdif";
			resets = <&ccu RST_BUS_SPDIF>;
			dmas = <&dma 2>;
			dma-names = "tx";
			#sound-dai-cells = <0>;
			status = "okay";
			pinctrl-names = "default";
			pinctrl-0 = <&spdif_pins_a>;
		};

		ahub: audio-hub@5097000 {
			#sound-dai-cells = <1>;
			compatible = "allwinner,sun50i-h616-ahub";
			reg = <0x05097000 0xb00>;
			clocks = <&ccu CLK_BUS_AUDIO_HUB>, <&ccu CLK_AUDIO_HUB>;
			clock-names = "bus", "mod";
			resets = <&ccu RST_BUS_AUDIO_HUB>;
			dmas = <&dma 3>, <&dma 3>, <&dma 4>, <&dma 4>,
			       <&dma 5>, <&dma 5>;
			dma-names = "tx0", "rx0", "tx1", "rx1", "tx2", "rx2";
			status = "okay";
		};

		emac0: ethernet@5020000 {
			compatible = "allwinner,sun50i-h616-emac0",
				     "allwinner,sun50i-a64-emac";
			reg = <0x05020000 0x10000>;
			interrupts = <GIC_SPI 14 IRQ_TYPE_LEVEL_HIGH>;
			interrupt-names = "macirq";
			clocks = <&ccu CLK_BUS_EMAC0>;
			clock-names = "stmmaceth";
			resets = <&ccu RST_BUS_EMAC0>;
			reset-names = "stmmaceth";
			syscon = <&syscon>;
			phy-mode = "rgmii";
			status = "disabled";
			pinctrl-names = "default";
			pinctrl-0 = <&gmac0_pins_a>;
			allwinner,tx-delay-ps = <700>;
			allwinner,rx-delay-ps = <3100>;

			mdio0: mdio {
				compatible = "snps,dwmac-mdio";
				#address-cells = <1>;
				#size-cells = <0>;
			};
		};

		emac1: ethernet@5030000 {
			compatible = "allwinner,sun50i-h616-emac1";
			syscon = <&syscon>;
			reg = <0x05030000 0x10000>;
			interrupts = <GIC_SPI 15 IRQ_TYPE_LEVEL_HIGH>;
			interrupt-names = "macirq";
			resets = <&ccu RST_BUS_EMAC1>;
			reset-names = "stmmaceth";
			clocks = <&ccu CLK_BUS_EMAC1>;
			clock-names = "stmmaceth";
			phy-mode = "rmii";
			status = "okay";
			pinctrl-names = "default";
			pinctrl-0 = <&gmac1_pins_a>;
			allwinner,tx-delay-ps = <700>;
			allwinner,rx-delay-ps = <3100>;

			mdio1: mdio {
				compatible = "snps,dwmac-mdio";
				#address-cells = <1>;
				#size-cells = <0>;

				/*
				 * Some SoCs have an AC300 EPHY instead of the
				 * AC200 one. The bootloader enables this node
				 * on those, based on the SID.
				 */
				ac300_ephy_package: ethernet-phy-package@0 {
					compatible = "x-powers,ac300-ephy-package";
					reg = <0>;
					#address-cells = <1>;
					#size-cells = <0>;
					clocks = <&ac200_pwm_clk>;
					nvmem-cells = <&ephy_config>;
					nvmem-cell-names = "configuration";
					status = "disabled";

					ac300_ephy: ethernet-phy@0 {
						compatible = "ethernet-phy-id0044.1400";
						reg = <0>;
					};
				};
			};
		};

		usbotg: usb@5100000 {
			compatible = "allwinner,sun50i-h616-musb",
				     "allwinner,sun8i-h3-musb";
			reg = <0x05100000 0x0400>;
			clocks = <&ccu CLK_BUS_OTG>;
			resets = <&ccu RST_BUS_OTG>;
			interrupts = <GIC_SPI 25 IRQ_TYPE_LEVEL_HIGH>;
			interrupt-names = "mc";
			phys = <&usbphy 0>;
			phy-names = "usb";
			extcon = <&usbphy 0>;
			status = "okay";
			dr_mode = "host";
		};

		ehci0: usb@5101000 {
			compatible = "allwinner,sun50i-h616-ehci",
				     "generic-ehci";
			reg = <0x05101000 0x100>;
			interrupts = <GIC_SPI 26 IRQ_TYPE_LEVEL_HIGH>;
			clocks = <&ccu CLK_BUS_OHCI0>,
				 <&ccu CLK_BUS_EHCI0>,
				 <&ccu CLK_USB_OHCI0>;
			resets = <&ccu RST_BUS_OHCI0>,
				 <&ccu RST_BUS_EHCI0>;
			phys = <&usbphy 0>;
			phy-names = "usb";
			status = "okay";
		};

		ohci0: usb@5101400 {
			compatible = "allwinner,sun50i-h616-ohci",
				     "generic-ohci";
			reg = <0x05101400 0x100>;
			interrupts = <GIC_SPI 27 IRQ_TYPE_LEVEL_HIGH>;
			clocks = <&ccu CLK_BUS_OHCI0>,
				 <&ccu CLK_USB_OHCI0>;
			resets = <&ccu RST_BUS_OHCI0>;
			phys = <&usbphy 0>;
			phy-names = "usb";
			status = "okay";
		};

		ehci1: usb@5200000 {
			compatible = "allwinner,sun50i-h616-ehci",
				     "generic-ehci";
			reg = <0x05200000 0x100>;
			interrupts = <GIC_SPI 28 IRQ_TYPE_LEVEL_HIGH>;
			clocks = <&ccu CLK_BUS_OHCI1>,
				 <&ccu CLK_BUS_EHCI1>,
				 <&ccu CLK_USB_OHCI1>;
			resets = <&ccu RST_BUS_OHCI1>,
				 <&ccu RST_BUS_EHCI1>;
			phys = <&usbphy 1>;
			phy-names = "usb";
			status = "okay";
		};

		ohci1: usb@5200400 {
			compatible = "allwinner,sun50i-h616-ohci",
				     "generic-ohci";
			reg = <0x05200400 0x100>;
			interrupts = <GIC_SPI 29 IRQ_TYPE_LEVEL_HIGH>;
			clocks = <&ccu CLK_BUS_OHCI1>,
				 <&ccu CLK_USB_OHCI1>;
			resets = <&ccu RST_BUS_OHCI1>;
			phys = <&usbphy 1>;
			phy-names = "usb";
			status = "okay";
		};

		ehci2: usb@5310000 {
			compatible = "allwinner,sun50i-h616-ehci",
				     "generic-ehci";
			reg = <0x05310000 0x100>;
			interrupts = <GIC_SPI 30 IRQ_TYPE_LEVEL_HIGH>;
			clocks = <&ccu CLK_BUS_OHCI2>,
				 <&ccu CLK_BUS_EHCI2>,
				 <&ccu CLK_USB_OHCI2>;
			resets = <&ccu RST_BUS_OHCI2>,
				 <&ccu RST_BUS_EHCI2>;
			phys = <&usbphy 2>;
			phy-names = "usb";
			status = "okay";
		};

		ohci2: usb@5310400 {
			compatible = "allwinner,sun50i-h616-ohci",
				     "generic-ohci";
			reg = <0x05310400 0x100>;
			interrupts = <GIC_SPI 31 IRQ_TYPE_LEVEL_HIGH>;
			clocks = <&ccu CLK_BUS_OHCI2>,
				 <&ccu CLK_USB_OHCI2>;
			resets = <&ccu RST_BUS_OHCI2>;
			phys = <&usbphy 2>;
			phy-names = "usb";
			status = "okay";
		};

		ehci3: usb@5311000 {
			compatible = "allwinner,sun50i-h616-ehci",
				     "generic-ehci";
			reg = <0x05311000 0x100>;
			interrupts = <GIC_SPI 32 IRQ_TYPE_LEVEL_HIGH>;
			clocks = <&ccu CLK_BUS_OHCI3>,
				 <&ccu CLK_BUS_EHCI3>,
				 <&ccu CLK_USB_OHCI3>;
			resets = <&ccu RST_BUS_OHCI3>,
				 <&ccu RST_BUS_EHCI3>;
			phys = <&usbphy 3>;
			phy-names = "usb";
			status = "okay";
		};

		ohci3: usb@5311400 {
			compatible = "allwinner,sun50i-h616-ohci",
				     "generic-ohci";
			reg = <0x05311400 0x100>;
			interrupts = <GIC_SPI 33 IRQ_TYPE_LEVEL_HIGH>;
			clocks = <&ccu CLK_BUS_OHCI3>,
				 <&ccu CLK_USB_OHCI3>;
			resets = <&ccu RST_BUS_OHCI3>;
			phys = <&usbphy 3>;
			phy-names = "usb";
			status = "okay";
		};

		hdmi: hdmi@6000000 {
			#sound-dai-cells = <0>;
			compatible = "allwinner,sun50i-h616-dw-hdmi",
				     "allwinner,sun50i-h6-dw-hdmi";
			reg = <0x06000000 0x10000>;
			reg-io-width = <1>;
			interrupts = <GIC_SPI 63 IRQ_TYPE_LEVEL_HIGH>;
			clocks = <&ccu CLK_BUS_HDMI>, <&ccu CLK_HDMI_SLOW>,
				 <&ccu CLK_HDMI>, <&ccu CLK_HDMI_CEC>,
				 <&ccu CLK_HDCP>, <&ccu CLK_BUS_HDCP>;
			clock-names = "iahb", "isfr", "tmds", "cec", "hdcp",
				      "hdcp-bus";
			resets = <&ccu RST_BUS_HDMI>, <&ccu RST_BUS_HDCP>;
			reset-names = "ctrl", "hdcp";
			phys = <&hdmi_phy>;
			phy-names = "phy";
			status = "okay";

			ports {
				#address-cells = <1>;
				#size-cells = <0>;

				hdmi_in: port@0 {
					reg = <0>;

					hdmi_in_tcon_top: endpoint {
						remote-endpoint = <&tcon_top_hdmi_out_hdmi>;
					};
				};

				hdmi_out: port@1 {
					reg = <1>;

					hdmi_out_con: endpoint {
						remote-endpoint = <&hdmi_con_in>;
					};
				};
			};
		};

		nmi_intc: interrupt-controller@7010320 {
			compatible = "allwinner,sun50i-h616-nmi",
				     "allwinner,sun9i-a80-nmi";
			reg = <0x07010320 0xc>;
			interrupt-controller;
			#interrupt-cells = <2>;
			interrupts = <GIC_SPI 103 IRQ_TYPE_LEVEL_HIGH>;
		};

		ir: ir@7040000 {
			compatible = "allwinner,sun50i-h616-ir",
				     "allwinner,sun6i-a31-ir";
			reg = <0x07040000 0x400>;
			interrupts = <GIC_SPI 106 IRQ_TYPE_LEVEL_HIGH>;
			clocks = <&r_ccu CLK_R_APB1_IR>,
				 <&r_ccu CLK_IR>;
			clock-names = "apb", "ir";
			resets = <&r_ccu RST_R_APB1_IR>;
			status = "okay";
			pinctrl-names = "default";
			pinctrl-0 = <&s_cir0_pins_a>;
		};

		syscon: syscon@3000000 {
			compatible = "allwinner,sun50i-h616-system-control";
			reg = <0x03000000 0x1000>;
			#address-cells = <1>;
			#size-cells = <1>;
			ranges;

			/* SRAM C */
			sram@28000 {
				compatible = "mmio-sram";
				reg = <0x00028000 0x30000>;
				#address-cells = <1>;
				#size-cells = <1>;
				ranges = <0 0x00028000 0x30000>;

				/*
				 * 0x0 ~ 0x20000 is partial alias of VE SRAM below.
				 * 0x20000 ~ 0x2ffff is (partial?) alias of DE SRAM.
				 * However the whole region is toggled together.
				 */
				sram_c: sram-section@0 {
					compatible = "allwinner,sun50i-h616-sram-c",
						     "allwinner,sun50i-a64-sram-c";
					reg = <0x00000 0x30000>;
				};
			};

			/* VE SRAM */
			sram@1a00000 {
				compatible = "mmio-sram";
				reg = <0x01a00000 0x200000>;
				#address-cells = <1>;
				#size-cells = <1>;
				ranges = <0 0x01a00000 0x200000>;

				ve_sram: sram-section@0 {
					compatible = "allwinner,sun50i-h616-ve-sram";
					reg = <0x000000 0x200000>;
				};
			};
		};

		sid: efuse@3006000 {
			compatible = "allwinner,sun50i-h616-sid", "allwinner,sun50i-a64-sid";
			reg = <0x03006000 0x1000>;
			#address-cells = <1>;
			#size-cells = <1>;

			ths_calibration: thermal-sensor-calibration@14 {
				reg = <0x14 0x8>;
			};

			cpu_speed_grade: cpu-speed-grade@0 {
				reg = <0x0 2>;
			};

			ephy_config: ephy-config@2c {
				reg = <0x2c 0x2>;
			};

			tve_calibration: tve-calibration@2c {
				reg = <0x2c 0x4>;
			};
		};

		timer0: timer@3009000 {
			compatible = "allwinner,sun50i-h616-timer",
				     "allwinner,sun8i-a23-timer";
			reg = <0x03009000 0xa0>;
			interrupts = <GIC_SPI 48 IRQ_TYPE_LEVEL_HIGH>,
				     <GIC_SPI 49 IRQ_TYPE_LEVEL_HIGH>;
			clocks = <&osc24M>;
		};

		hstimer@3005000 {
			compatible = "allwinner,sun50i-h616-hstimer",
				     "allwinner,sun20i-d1-hstimer";
			reg = <0x03005000 0x1000>;
			interrupts = <GIC_SPI 45 IRQ_TYPE_LEVEL_HIGH>,
				     <GIC_SPI 46 IRQ_TYPE_LEVEL_HIGH>;
			clocks = <&ccu CLK_BUS_HSTIMER>;
			resets = <&ccu RST_BUS_HSTIMER>;
		};

		nfc: nand-controller@4011000 {
			compatible = "allwinner,sun50i-h616-nand-controller";
			reg = <0x04011000 0x1000>;
			interrupts = <GIC_SPI 34 IRQ_TYPE_LEVEL_HIGH>;
			clocks = <&ccu CLK_BUS_NAND>, <&ccu CLK_NAND0>,
				 <&ccu CLK_NAND1>, <&ccu CLK_MBUS_NAND>;
			clock-names = "ahb", "mod", "ecc", "mbus";
			resets = <&ccu RST_BUS_NAND>;
			reset-names = "ahb";
			dmas = <&dma 10>;
			dma-names = "rxtx";
			#address-cells = <1>;
			#size-cells = <0>;
			status = "disabled";
		};

		lradc: lradc@5070800 {
			compatible = "allwinner,sun50i-h616-lradc",
				     "allwinner,sun50i-r329-lradc";
			reg = <0x05070800 0x400>;
			interrupts = <GIC_SPI 20 IRQ_TYPE_LEVEL_HIGH>;
			clocks = <&ccu CLK_BUS_KEYADC>;
			resets = <&ccu RST_BUS_KEYADC>;
			status = "disabled";
		};

		usbphy: phy@5100400 {
			compatible = "allwinner,sun50i-h616-usb-phy";
			reg = <0x05100400 0x24>,
			      <0x05101800 0x14>,
			      <0x05200800 0x14>,
			      <0x05310800 0x14>,
			      <0x05311800 0x14>;
			reg-names = "phy_ctrl",
				    "pmu0",
				    "pmu1",
				    "pmu2",
				    "pmu3";
			clocks = <&ccu CLK_USB_PHY0>,
				 <&ccu CLK_USB_PHY1>,
				 <&ccu CLK_USB_PHY2>,
				 <&ccu CLK_USB_PHY3>,
				 <&ccu CLK_BUS_EHCI2>;
			clock-names = "usb0_phy",
				      "usb1_phy",
				      "usb2_phy",
				      "usb3_phy",
				      "pmu2_clk";
			resets = <&ccu RST_USB_PHY0>,
				 <&ccu RST_USB_PHY1>,
				 <&ccu RST_USB_PHY2>,
				 <&ccu RST_USB_PHY3>;
			reset-names = "usb0_reset",
				      "usb1_reset",
				      "usb2_reset",
				      "usb3_reset";
			#phy-cells = <1>;
			usb0_vbus-supply = <&usb0_drvvbus>;
			usb1_vbus-supply = <&usb0_drvvbus>;
			usb2_vbus-supply = <&usb0_drvvbus>;
			status = "okay";
			usb3_vbus-supply = <&usb0_drvvbus>;
		};

		hdmi_phy: hdmi-phy@6010000 {
			compatible = "allwinner,sun50i-h616-hdmi-phy";
			reg = <0x06010000 0x10000>;
			clocks = <&ccu CLK_BUS_HDMI>, <&ccu CLK_HDMI_SLOW>;
			clock-names = "bus", "mod";
			resets = <&ccu RST_BUS_HDMI_SUB>;
			reset-names = "phy";
			#phy-cells = <0>;
		};

		tcon_top: tcon-top@6510000 {
			compatible = "allwinner,sun50i-h616-tcon-top";
			reg = <0x06510000 0x1000>;
			clocks = <&ccu CLK_BUS_TCON_TOP>,
				 <&ccu CLK_TCON_TV0>,
				 <&ccu CLK_TVE0>,
				 <&ccu CLK_TCON_TV1>;
			clock-names = "bus",
				      "tcon-tv0",
				      "tve0",
				      "tcon-tv1";
			clock-output-names = "tcon-top-tv0",
					     "tcon-top-tv1";
			resets = <&ccu RST_BUS_TCON_TOP>;
			#clock-cells = <1>;

			ports {
				#address-cells = <1>;
				#size-cells = <0>;

				tcon_top_mixer0_in: port@0 {
					#address-cells = <1>;
					#size-cells = <0>;
					reg = <0>;

					tcon_top_mixer0_in_mixer0: endpoint@0 {
						reg = <0>;
						remote-endpoint = <&mixer0_out_tcon_top_mixer0>;
					};
				};

				tcon_top_mixer0_out: port@1 {
					#address-cells = <1>;
					#size-cells = <0>;
					reg = <1>;

					tcon_top_mixer0_out_tcon_lcd0: endpoint@0 {
						reg = <0>;
						remote-endpoint = <&tcon_lcd0_in_tcon_top_mixer0>;
					};

					tcon_top_mixer0_out_tcon_lcd1: endpoint@1 {
						reg = <1>;
						remote-endpoint = <&tcon_lcd1_in_tcon_top_mixer0>;
					};

					tcon_top_mixer0_out_tcon_tv0: endpoint@2 {
						reg = <2>;
						remote-endpoint = <&tcon_tv0_in_tcon_top_mixer0>;
					};

					tcon_top_mixer0_out_tcon_tv1: endpoint@3 {
						reg = <3>;
						remote-endpoint = <&tcon_tv1_in_tcon_top_mixer0>;
					};
				};

				tcon_top_mixer1_in: port@2 {
					#address-cells = <1>;
					#size-cells = <0>;
					reg = <2>;

					tcon_top_mixer1_in_mixer1: endpoint@1 {
						reg = <1>;
						remote-endpoint = <&mixer1_out_tcon_top_mixer1>;
					};
				};

				tcon_top_mixer1_out: port@3 {
					#address-cells = <1>;
					#size-cells = <0>;
					reg = <3>;

					tcon_top_mixer1_out_tcon_lcd0: endpoint@0 {
						reg = <0>;
						remote-endpoint = <&tcon_lcd0_in_tcon_top_mixer1>;
					};

					tcon_top_mixer1_out_tcon_lcd1: endpoint@1 {
						reg = <1>;
						remote-endpoint = <&tcon_lcd1_in_tcon_top_mixer1>;
					};

					tcon_top_mixer1_out_tcon_tv0: endpoint@2 {
						reg = <2>;
						remote-endpoint = <&tcon_tv0_in_tcon_top_mixer1>;
					};

					tcon_top_mixer1_out_tcon_tv1: endpoint@3 {
						reg = <3>;
						remote-endpoint = <&tcon_tv1_in_tcon_top_mixer1>;
					};
				};

				tcon_top_hdmi_in: port@4 {
					#address-cells = <1>;
					#size-cells = <0>;
					reg = <4>;

					tcon_top_hdmi_in_tcon_tv0: endpoint@0 {
						reg = <0>;
						remote-endpoint = <&tcon_tv0_out_tcon_top>;
					};

					tcon_top_hdmi_in_tcon_tv1: endpoint@1 {
						reg = <1>;
						remote-endpoint = <&tcon_tv1_out_tcon_top>;
					};
				};

				tcon_top_hdmi_out: port@5 {
					reg = <5>;

					tcon_top_hdmi_out_hdmi: endpoint {
						remote-endpoint = <&hdmi_in_tcon_top>;
					};
				};
			};
		};

		tcon_lcd0: lcd-controller@6511000 {
			compatible = "allwinner,sun50i-h616-tcon-lcd",
				     "allwinner,sun8i-r40-tcon-lcd";
			reg = <0x06511000 0x1000>;
			interrupts = <GIC_SPI 64 IRQ_TYPE_LEVEL_HIGH>;
			clocks = <&ccu CLK_BUS_TCON_LCD0>, <&ccu CLK_TCON_LCD0>;
			clock-names = "ahb", "tcon-ch0";
			clock-output-names = "tcon-data-clock";
			#clock-cells = <0>;
			resets = <&ccu RST_BUS_TCON_LCD0>, <&ccu RST_BUS_LVDS>;
			reset-names = "lcd", "lvds";
			status = "disabled";

			ports {
				#address-cells = <1>;
				#size-cells = <0>;

				tcon_lcd0_in: port@0 {
					#address-cells = <1>;
					#size-cells = <0>;
					reg = <0>;

					tcon_lcd0_in_tcon_top_mixer0: endpoint@0 {
						reg = <0>;
						remote-endpoint = <&tcon_top_mixer0_out_tcon_lcd0>;
					};

					tcon_lcd0_in_tcon_top_mixer1: endpoint@1 {
						reg = <1>;
						remote-endpoint = <&tcon_top_mixer1_out_tcon_lcd0>;
					};
				};

				tcon_lcd0_out: port@1 {
					reg = <1>;
				};
			};
		};

		tcon_lcd1: lcd-controller@6512000 {
			compatible = "allwinner,sun50i-h616-tcon-lcd",
				     "allwinner,sun8i-r40-tcon-lcd";
			reg = <0x06512000 0x1000>;
			interrupts = <GIC_SPI 65 IRQ_TYPE_LEVEL_HIGH>;
			clocks = <&ccu CLK_BUS_TCON_LCD1>, <&ccu CLK_TCON_LCD1>;
			clock-names = "ahb", "tcon-ch0";
			clock-output-names = "tcon-data-clock";
			#clock-cells = <0>;
			resets = <&ccu RST_BUS_TCON_LCD1>, <&ccu RST_BUS_LVDS>;
			reset-names = "lcd", "lvds";
			status = "disabled";

			ports {
				#address-cells = <1>;
				#size-cells = <0>;

				tcon_lcd1_in: port@0 {
					#address-cells = <1>;
					#size-cells = <0>;
					reg = <0>;

					tcon_lcd1_in_tcon_top_mixer0: endpoint@0 {
						reg = <0>;
						remote-endpoint = <&tcon_top_mixer0_out_tcon_lcd1>;
					};

					tcon_lcd1_in_tcon_top_mixer1: endpoint@1 {
						reg = <1>;
						remote-endpoint = <&tcon_top_mixer1_out_tcon_lcd1>;
					};
				};

				tcon_lcd1_out: port@1 {
					reg = <1>;
				};
			};
		};

		tcon_tv0: lcd-controller@6515000 {
			compatible = "allwinner,sun50i-h616-tcon-tv";
			reg = <0x06515000 0x1000>;
			interrupts = <GIC_SPI 66 IRQ_TYPE_LEVEL_HIGH>;
			clocks = <&ccu CLK_BUS_TCON_TV0>,
				 <&tcon_top CLK_TCON_TOP_TV0>;
			clock-names = "ahb",
				      "tcon-ch1";
			resets = <&ccu RST_BUS_TCON_TV0>;
			reset-names = "lcd";

			ports {
				#address-cells = <1>;
				#size-cells = <0>;

				tcon_tv0_in: port@0 {
					#address-cells = <1>;
					#size-cells = <0>;
					reg = <0>;

					tcon_tv0_in_tcon_top_mixer0: endpoint@0 {
						reg = <0>;
						remote-endpoint = <&tcon_top_mixer0_out_tcon_tv0>;
					};

					tcon_tv0_in_tcon_top_mixer1: endpoint@1 {
						reg = <1>;
						remote-endpoint = <&tcon_top_mixer1_out_tcon_tv0>;
					};
				};

				tcon_tv0_out: port@1 {
					#address-cells = <1>;
					#size-cells = <0>;
					reg = <1>;

					tcon_tv0_out_tcon_top: endpoint@1 {
						reg = <1>;
						remote-endpoint = <&tcon_top_hdmi_in_tcon_tv0>;
					};
				};
			};
		};

		tcon_tv1: lcd-controller@6516000 {
			compatible = "allwinner,sun50i-h616-tcon-tv";
			reg = <0x06516000 0x1000>;
			interrupts = <GIC_SPI 67 IRQ_TYPE_LEVEL_HIGH>;
			clocks = <&ccu CLK_BUS_TCON_TV1>,
				 <&tcon_top CLK_TCON_TOP_TV1>;
			clock-names = "ahb",
				      "tcon-ch1";
			resets = <&ccu RST_BUS_TCON_TV1>;
			reset-names = "lcd";

			ports {
				#address-cells = <1>;
				#size-cells = <0>;

				tcon_tv1_in: port@0 {
					#address-cells = <1>;
					#size-cells = <0>;
					reg = <0>;

					tcon_tv1_in_tcon_top_mixer0: endpoint@0 {
						reg = <0>;
						remote-endpoint = <&tcon_top_mixer0_out_tcon_tv1>;
					};

					tcon_tv1_in_tcon_top_mixer1: endpoint@1 {
						reg = <1>;
						remote-endpoint = <&tcon_top_mixer1_out_tcon_tv1>;
					};
				};

				tcon_tv1_out: port@1 {
					#address-cells = <1>;
					#size-cells = <0>;
					reg = <1>;

					tcon_tv1_out_tcon_top: endpoint@1 {
						reg = <1>;
						remote-endpoint = <&tcon_top_hdmi_in_tcon_tv1>;
					};

					tcon_tv1_out_tve: endpoint@2 {
						reg = <2>;
						remote-endpoint = <&tve_in_tcon_tv1>;
					};
				};
			};
		};

		tve: tv-encoder@6524000 {
			compatible = "allwinner,sun50i-h616-tv-encoder";
			reg = <0x06524000 0x400>, <0x06520000 0x100>;
			clocks = <&ccu CLK_BUS_TVE0>, <&ccu CLK_TVE0>,
				 <&ccu CLK_BUS_TVE_TOP>;
			resets = <&ccu RST_BUS_TVE0>, <&ccu RST_BUS_TVE_TOP>;
			assigned-clocks = <&ccu CLK_TVE0>;
			/* PLL-VIDEO1, which the binding header does not export */
			assigned-clock-parents = <&ccu 11>;
			assigned-clock-rates = <216000000>;
			nvmem-cells = <&tve_calibration>;
			nvmem-cell-names = "calibration";
			status = "disabled";

			port {
				tve_in_tcon_tv1: endpoint {
					remote-endpoint = <&tcon_tv1_out_tve>;
				};
			};
		};

		prcm_ppu: power-controller@7010250 {
			compatible = "allwinner,sun50i-h616-prcm-ppu";
			reg = <0x07010250 0x10>;
			#power-domain-cells = <1>;
		};

		r_rsb: rsb@7083000 {
			compatible = "allwinner,sun50i-h616-rsb",
				     "allwinner,sun8i-a23-rsb";
			reg = <0x07083000 0x400>;
			interrupts = <GIC_SPI 109 IRQ_TYPE_LEVEL_HIGH>;
			clocks = <&r_ccu CLK_R_APB2_RSB>;
			clock-frequency = <3000000>;
			resets = <&r_ccu RST_R_APB2_RSB>;
			pinctrl-names = "default";
			pinctrl-0 = <&r_rsb_pins>;
			status = "disabled";
			#address-cells = <1>;
			#size-cells = <0>;
		};

		gic: interrupt-controller@3021000 {
			compatible = "arm,gic-400";
			reg = <0x03021000 0x1000>,
			      <0x03022000 0x2000>,
			      <0x03024000 0x2000>,
			      <0x03026000 0x2000>;
			interrupts = <GIC_PPI 9 (GIC_CPU_MASK_SIMPLE(4) | IRQ_TYPE_LEVEL_HIGH)>;
			interrupt-controller;
			#interrupt-cells = <3>;
		};
	};

	thermal-zones {
		cpu-thermal {
			polling-delay-passive = <500>;
			polling-delay = <1000>;
			thermal-sensors = <&ths 2>;
			sustainable-power = <927>;

			trips {
				cpu_threshold: cpu-trip-0 {
					temperature = <70000>;
					type = "passive";
					hysteresis = <0>;
				};

				cpu_target: cpu-trip-1 {
					temperature = <90000>;
					type = "passive";
					hysteresis = <0>;
				};

				cpu_critical: cpu-trip-2 {
					temperature = <115000>;
					type = "critical";
					hysteresis = <0>;
				};
			};

			cooling-maps {
				map0 {
					trip = <&cpu_target>;
					cooling-device = <&cpu0 THERMAL_NO_LIMIT THERMAL_NO_LIMIT>;
					contribution = <1024>;
				};

				map1 {
					trip = <&cpu_target>;
					cooling-device = <&gpu THERMAL_NO_LIMIT THERMAL_NO_LIMIT>;
					contribution = <1024>;
				};
			};
		};

		ddr-thermal {
			polling-delay-passive = <0>;
			polling-delay = <0>;
			thermal-sensors = <&ths 3>;

			trips {
				ddr_temp_critical: ddr-trip-0 {
					temperature = <110000>;
					type = "critical";
					hysteresis = <0>;
				};
			};
		};

		gpu-thermal {
			polling-delay-passive = <500>;
			polling-delay = <1000>;
			thermal-sensors = <&ths 0>;
			sustainable-power = <1100>;

			trips {
				gpu_temp_critical: gpu-trip-0 {
					temperature = <110000>;
					type = "critical";
					hysteresis = <0>;
				};
			};
		};

		ve-thermal {
			polling-delay-passive = <0>;
			polling-delay = <0>;
			thermal-sensors = <&ths 1>;

			trips {
				ve_temp_critical: ve-trip-0 {
					temperature = <110000>;
					type = "critical";
					hysteresis = <0>;
				};
			};
		};
	};

	usb0_drvvbus: usb0-drvvvbus {
		compatible = "regulator-fixed";
		regulator-name = "usb0-drvvbus";
		regulator-min-microvolt = <5000000>;
		regulator-max-microvolt = <5000000>;
		regulator-enable-ramp-delay = <1000>;
		gpio = <&pio 7 8 GPIO_ACTIVE_HIGH>;
		enable-active-high;
	};

	de: display-engine {
		compatible = "allwinner,sun50i-h616-display-engine";
		allwinner,pipelines = <&mixer0>, <&mixer1>;
		status = "okay";
	};

	hdmi_sound: sound-hdmi {
		compatible = "allwinner,sun8i-a83t-hdmi-audio";
		audio-cpu = <&ahub 1>;
		audio-codec = <&hdmi>;
		status = "okay";
	};

	osc24M: osc24M-clk {
		#clock-cells = <0>;
		compatible = "fixed-clock";
		clock-frequency = <24000000>;
		clock-output-names = "osc24M";
	};

	pmu {
		compatible = "arm,cortex-a53-pmu";
		interrupts = <GIC_SPI 140 IRQ_TYPE_LEVEL_HIGH>,
			     <GIC_SPI 141 IRQ_TYPE_LEVEL_HIGH>,
			     <GIC_SPI 142 IRQ_TYPE_LEVEL_HIGH>,
			     <GIC_SPI 143 IRQ_TYPE_LEVEL_HIGH>;
		interrupt-affinity = <&cpu0>, <&cpu1>, <&cpu2>, <&cpu3>;
	};

	ac200_pwm_clk: ac200-clock {
		compatible = "pwm-clock";
		#clock-cells = <0>;
		clock-frequency = <24000000>;
		pinctrl-names = "default";
		pinctrl-0 = <&pwm5_pin>;
		pwms = <&pwm 5 42 0>;
		status = "disabled";
	};

	gpu_opp_table: opp-table-gpu {
		compatible = "operating-points-v2";

		opp-306000000 {
			opp-hz = /bits/ 64 <306000000>;
			opp-microvolt = <950000>;
		};

		opp-336000000 {
			opp-hz = /bits/ 64 <336000000>;
			opp-microvolt = <950000>;
		};

		opp-360000000 {
			opp-hz = /bits/ 64 <360000000>;
			opp-microvolt = <950000>;
		};

		opp-384000000 {
			opp-hz = /bits/ 64 <384000000>;
			opp-microvolt = <950000>;
		};

		opp-420000000 {
			opp-hz = /bits/ 64 <420000000>;
			opp-microvolt = <950000>;
		};

		opp-456000000 {
			opp-hz = /bits/ 64 <456000000>;
			opp-microvolt = <950000>;
		};

		opp-504000000 {
			opp-hz = /bits/ 64 <504000000>;
			opp-microvolt = <950000>;
		};

		opp-540000000 {
			opp-hz = /bits/ 64 <540000000>;
			opp-microvolt = <950000>;
		};

		opp-576000000 {
			opp-hz = /bits/ 64 <576000000>;
			opp-microvolt = <950000>;
		};

		opp-600000000 {
			opp-hz = /bits/ 64 <600000000>;
			opp-microvolt = <950000>;
		};
	};

	leds {
		compatible = "gpio-leds";

		led-0 {
			label = "power";
			function = LED_FUNCTION_POWER;
			gpios = <&pio 7 6 GPIO_ACTIVE_LOW>;
			default-state = "on";
			retain-state-suspended;
			retain-state-shutdown;
		};

		led-1 {
			label = "standby";
			function = LED_FUNCTION_STANDBY;
			gpios = <&pio 7 7 GPIO_ACTIVE_HIGH>;
			default-state = "off";
			retain-state-suspended;
			retain-state-shutdown;
		};
	};

	connector {
		compatible = "hdmi-connector";
		type = "a";

		port {
			hdmi_con_in: endpoint {
				remote-endpoint = <&hdmi_out_con>;
			};
		};
	};

	wifi_pwrseq: pwrseq {
		compatible = "mmc-pwrseq-simple";
		clocks = <&rtc CLK_OSC32K_FANOUT>;
		clock-names = "ext_clock";
		pinctrl-names = "default";
		pinctrl-0 = <&clk_losc_pins_a>;
		assigned-clocks = <&rtc CLK_OSC32K_FANOUT>;
		assigned-clock-parents = <&ccu CLK_PLL_SYSTEM_32K>;
		reset-gpios = <&pio 6 18 GPIO_ACTIVE_LOW>;
	};
};
